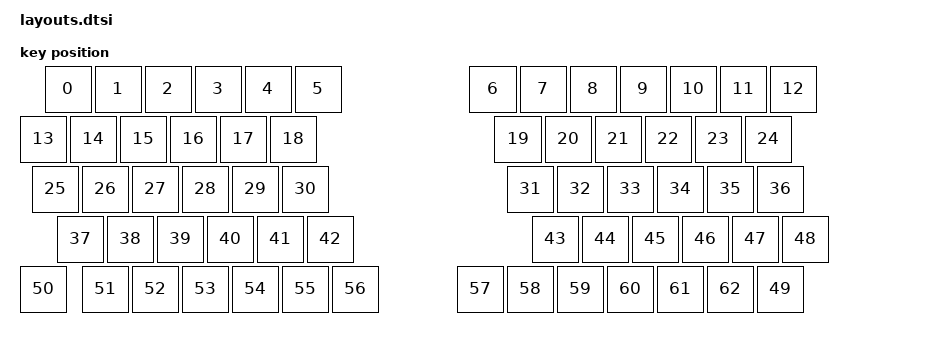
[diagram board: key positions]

#include <physical_layouts.dtsi>
/ {
    physical_layout0: physical_layout0 {
        compatible = "zmk,physical-layout";
        display-name = "Layout";
        keys
            = <&key_physical_attrs 100 100 0 0 0 0 0>
			,<&key_physical_attrs 100 100 100 0 0 0 0>
			,<&key_physical_attrs 100 100 200 0 0 0 0>
			,<&key_physical_attrs 100 100 300 0 0 0 0>
			,<&key_physical_attrs 100 100 400 0 0 0 0>
			,<&key_physical_attrs 100 100 500 0 0 0 0>
			,<&key_physical_attrs 100 100 850 0 0 0 0>
			,<&key_physical_attrs 100 100 950 0 0 0 0>
			,<&key_physical_attrs 100 100 1050 0 0 0 0>
			,<&key_physical_attrs 100 100 1150 0 0 0 0>
			,<&key_physical_attrs 100 100 1250 0 0 0 0>
			,<&key_physical_attrs 100 100 1350 0 0 0 0>
			,<&key_physical_attrs 100 100 1450 0 0 0 0>
			,<&key_physical_attrs 100 100 (-50) 100 0 0 0>
			,<&key_physical_attrs 100 100 50 100 0 0 0>
			,<&key_physical_attrs 100 100 150 100 0 0 0>
			,<&key_physical_attrs 100 100 250 100 0 0 0>
			,<&key_physical_attrs 100 100 350 100 0 0 0>
			,<&key_physical_attrs 100 100 450 100 0 0 0>
			,<&key_physical_attrs 100 100 900 100 0 0 0>
			,<&key_physical_attrs 100 100 1000 100 0 0 0>
			,<&key_physical_attrs 100 100 1100 100 0 0 0>
			,<&key_physical_attrs 100 100 1200 100 0 0 0>
			,<&key_physical_attrs 100 100 1300 100 0 0 0>
			,<&key_physical_attrs 100 100 1400 100 0 0 0>
			,<&key_physical_attrs 100 100 (-25) 200 0 0 0>
			,<&key_physical_attrs 100 100 75 200 0 0 0>
			,<&key_physical_attrs 100 100 175 200 0 0 0>
			,<&key_physical_attrs 100 100 275 200 0 0 0>
			,<&key_physical_attrs 100 100 375 200 0 0 0>
			,<&key_physical_attrs 100 100 475 200 0 0 0>
			,<&key_physical_attrs 100 100 925 200 0 0 0>
			,<&key_physical_attrs 100 100 1025 200 0 0 0>
			,<&key_physical_attrs 100 100 1125 200 0 0 0>
			,<&key_physical_attrs 100 100 1225 200 0 0 0>
			,<&key_physical_attrs 100 100 1325 200 0 0 0>
			,<&key_physical_attrs 100 100 1425 200 0 0 0>
			,<&key_physical_attrs 100 100 25 300 0 0 0>
			,<&key_physical_attrs 100 100 125 300 0 0 0>
			,<&key_physical_attrs 100 100 225 300 0 0 0>
			,<&key_physical_attrs 100 100 325 300 0 0 0>
			,<&key_physical_attrs 100 100 425 300 0 0 0>
			,<&key_physical_attrs 100 100 525 300 0 0 0>
			,<&key_physical_attrs 100 100 975 300 0 0 0>
			,<&key_physical_attrs 100 100 1075 300 0 0 0>
			,<&key_physical_attrs 100 100 1175 300 0 0 0>
			,<&key_physical_attrs 100 100 1275 300 0 0 0>
			,<&key_physical_attrs 100 100 1375 300 0 0 0>
			,<&key_physical_attrs 100 100 1475 300 0 0 0>
			,<&key_physical_attrs 100 100 1425 400 0 0 0>
			,<&key_physical_attrs 100 100 (-50) 400 0 0 0>
			,<&key_physical_attrs 100 100 75 400 0 0 0>
			,<&key_physical_attrs 100 100 175 400 0 0 0>
			,<&key_physical_attrs 100 100 275 400 0 0 0>
			,<&key_physical_attrs 100 100 375 400 0 0 0>
			,<&key_physical_attrs 100 100 475 400 0 0 0>
			,<&key_physical_attrs 100 100 575 400 0 0 0>
			,<&key_physical_attrs 100 100 825 400 0 0 0>
			,<&key_physical_attrs 100 100 925 400 0 0 0>
			,<&key_physical_attrs 100 100 1025 400 0 0 0>
			,<&key_physical_attrs 100 100 1125 400 0 0 0>
			,<&key_physical_attrs 100 100 1225 400 0 0 0>
			,<&key_physical_attrs 100 100 1325 400 0 0 0>
            ;
    };
};
    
